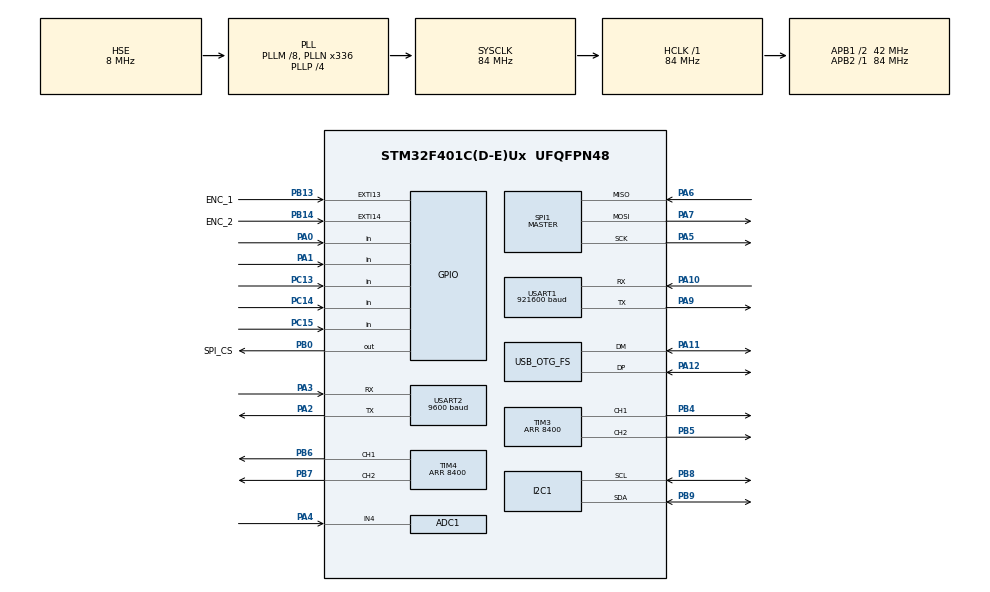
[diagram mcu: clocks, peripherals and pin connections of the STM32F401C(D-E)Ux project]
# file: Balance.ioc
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ADC1.Channel-0\#ChannelRegularConversion=ADC_CHANNEL_4
ADC1.ClockPrescaler=ADC_CLOCK_SYNC_PCLK_DIV4
ADC1.NbrOfConversionFlag=1
ADC1.Rank-0\#ChannelRegularConversion=1
ADC1.SamplingTime-0\#ChannelRegularConversion=ADC_SAMPLETIME_3CYCLES
ADC1.master=1
Dma.Request0=USART1_TX
Dma.Request1=USART1_RX
Dma.Request2=USART2_RX
Dma.Request3=USART2_TX
Dma.USART1_RX.1.Direction=DMA_PERIPH_TO_MEMORY
Dma.USART1_RX.1.FIFOMode=DMA_FIFOMODE_DISABLE
Dma.USART1_RX.1.Instance=DMA2_Stream2
Dma.USART1_RX.1.MemDataAlignment=DMA_MDATAALIGN_BYTE
Dma.USART1_RX.1.MemInc=DMA_MINC_ENABLE
Dma.USART1_RX.1.Mode=DMA_CIRCULAR
Dma.USART1_RX.1.PeriphDataAlignment=DMA_PDATAALIGN_BYTE
Dma.USART1_RX.1.PeriphInc=DMA_PINC_DISABLE
Dma.USART1_RX.1.Priority=DMA_PRIORITY_LOW
Dma.USART1_TX.0.Direction=DMA_MEMORY_TO_PERIPH
Dma.USART1_TX.0.FIFOMode=DMA_FIFOMODE_DISABLE
Dma.USART1_TX.0.Instance=DMA2_Stream7
Dma.USART1_TX.0.MemDataAlignment=DMA_MDATAALIGN_BYTE
Dma.USART1_TX.0.MemInc=DMA_MINC_ENABLE
Dma.USART1_TX.0.Mode=DMA_NORMAL
Dma.USART1_TX.0.PeriphDataAlignment=DMA_PDATAALIGN_BYTE
Dma.USART1_TX.0.PeriphInc=DMA_PINC_DISABLE
Dma.USART1_TX.0.Priority=DMA_PRIORITY_LOW
Dma.USART2_RX.2.Direction=DMA_PERIPH_TO_MEMORY
Dma.USART2_RX.2.FIFOMode=DMA_FIFOMODE_DISABLE
Dma.USART2_RX.2.Instance=DMA1_Stream5
Dma.USART2_RX.2.MemDataAlignment=DMA_MDATAALIGN_BYTE
Dma.USART2_RX.2.MemInc=DMA_MINC_ENABLE
Dma.USART2_RX.2.Mode=DMA_CIRCULAR
Dma.USART2_RX.2.PeriphDataAlignment=DMA_PDATAALIGN_BYTE
Dma.USART2_RX.2.PeriphInc=DMA_PINC_DISABLE
Dma.USART2_RX.2.Priority=DMA_PRIORITY_LOW
Dma.USART2_TX.3.Direction=DMA_MEMORY_TO_PERIPH
Dma.USART2_TX.3.FIFOMode=DMA_FIFOMODE_DISABLE
Dma.USART2_TX.3.Instance=DMA1_Stream6
Dma.USART2_TX.3.MemDataAlignment=DMA_MDATAALIGN_BYTE
Dma.USART2_TX.3.MemInc=DMA_MINC_ENABLE
Dma.USART2_TX.3.Mode=DMA_NORMAL
Dma.USART2_TX.3.PeriphDataAlignment=DMA_PDATAALIGN_BYTE
Dma.USART2_TX.3.PeriphInc=DMA_PINC_DISABLE
Dma.USART2_TX.3.Priority=DMA_PRIORITY_LOW
I2C1.I2C_Mode=I2C_Fast
Mcu.Family=STM32F4
Mcu.Name=STM32F401C(D-E)Ux
Mcu.Package=UFQFPN48
NVIC.DMA1_Stream5_IRQn=true\:3\:0\:true\:false\:true\:false\:true
NVIC.DMA1_Stream6_IRQn=true\:3\:0\:true\:false\:true\:false\:true
NVIC.DMA2_Stream2_IRQn=true\:3\:0\:true\:false\:true\:false\:true
NVIC.DMA2_Stream7_IRQn=true\:3\:0\:true\:false\:true\:false\:true
NVIC.EXTI15_10_IRQn=true\:2\:0\:true\:false\:true\:true\:true
NVIC.OTG_FS_IRQn=true\:2\:0\:true\:false\:true\:false\:true
NVIC.PriorityGroup=NVIC_PRIORITYGROUP_4
NVIC.TIM1_TRG_COM_TIM11_IRQn=true\:1\:0\:true\:false\:true\:true\:true
NVIC.TIM1_UP_TIM10_IRQn=true\:3\:0\:true\:false\:true\:false\:true
NVIC.TimeBase=TIM1_UP_TIM10_IRQn
NVIC.TimeBaseIP=TIM10
NVIC.USART1_IRQn=true\:3\:0\:true\:false\:true\:true\:true
NVIC.USART2_IRQn=true\:3\:0\:true\:false\:true\:true\:true
PA0-WKUP.Signal=GPIO_Input
PA1.Signal=GPIO_Input
PA10.Mode=Asynchronous
PA10.Signal=USART1_RX
PA11.Mode=Device_Only
PA11.Signal=USB_OTG_FS_DM
PA12.Mode=Device_Only
PA12.Signal=USB_OTG_FS_DP
PA13.Mode=Serial_Wire
PA13.Signal=SYS_JTMS-SWDIO
PA14.Mode=Serial_Wire
PA14.Signal=SYS_JTCK-SWCLK
PA2.Mode=Asynchronous
PA2.Signal=USART2_TX
PA3.Mode=Asynchronous
PA3.Signal=USART2_RX
PA4.Signal=ADCx_IN4
PA5.Mode=Full_Duplex_Master
PA5.Signal=SPI1_SCK
PA6.Mode=Full_Duplex_Master
PA6.Signal=SPI1_MISO
PA7.Mode=Full_Duplex_Master
PA7.Signal=SPI1_MOSI
PA9.Mode=Asynchronous
PA9.Signal=USART1_TX
PB0.GPIO_Label=SPI_CS
PB0.GPIO_PuPd=GPIO_PULLUP
PB0.GPIO_Speed=GPIO_SPEED_FREQ_HIGH
PB0.PinState=GPIO_PIN_SET
PB0.Signal=GPIO_Output
PB13.GPIO_Label=ENC_1
PB13.GPIO_ModeDefaultEXTI=GPIO_MODE_IT_RISING_FALLING
PB13.Signal=GPXTI13
PB14.GPIO_Label=ENC_2
PB14.GPIO_ModeDefaultEXTI=GPIO_MODE_IT_RISING_FALLING
PB14.Signal=GPXTI14
PB4.Signal=S_TIM3_CH1
PB5.Signal=S_TIM3_CH2
PB6.Signal=S_TIM4_CH1
PB7.Signal=S_TIM4_CH2
PB8.Mode=I2C
PB8.Signal=I2C1_SCL
PB9.Mode=I2C
PB9.Signal=I2C1_SDA
PC13-ANTI_TAMP.Signal=GPIO_Input
PC14-OSC32_IN.Signal=GPIO_Input
PC15-OSC32_OUT.Signal=GPIO_Input
PH0\ -\ OSC_IN.Mode=HSE-External-Oscillator
PH0\ -\ OSC_IN.Signal=RCC_OSC_IN
PH1\ -\ OSC_OUT.Mode=HSE-External-Oscillator
PH1\ -\ OSC_OUT.Signal=RCC_OSC_OUT
ProjectManager.HeapSize=0x100
ProjectManager.StackSize=0xA00
ProjectManager.TargetToolchain=MDK-ARM V5.27
RCC.48MHZClocksFreq_Value=48000000
RCC.AHBFreq_Value=84000000
RCC.APB1CLKDivider=RCC_HCLK_DIV2
RCC.APB1Freq_Value=42000000
RCC.APB1TimFreq_Value=84000000
RCC.APB2Freq_Value=84000000
RCC.APB2TimFreq_Value=84000000
RCC.CortexFreq_Value=84000000
RCC.HCLKFreq_Value=84000000
RCC.HSE_VALUE=8000000
RCC.HSI_VALUE=16000000
RCC.LSE_VALUE=32768
RCC.PLLM=8
RCC.PLLN=336
RCC.PLLP=RCC_PLLP_DIV4
RCC.PLLQ=7
RCC.SYSCLKFreq_VALUE=84000000
RCC.SYSCLKSource=RCC_SYSCLKSOURCE_PLLCLK
RCC.VCOOutputFreq_Value=336000000
SH.ADCx_IN4.0=ADC1_IN4,IN4
SH.S_TIM3_CH1.0=TIM3_CH1,PWM Generation1 CH1
SH.S_TIM3_CH2.0=TIM3_CH2,PWM Generation2 CH2
SH.S_TIM4_CH1.0=TIM4_CH1,PWM Generation1 CH1
SH.S_TIM4_CH2.0=TIM4_CH2,PWM Generation2 CH2
SPI1.Direction=SPI_DIRECTION_2LINES
SPI1.Mode=SPI_MODE_MASTER
SPI1.VirtualType=VM_MASTER
TIM11.AutoReloadPreload=TIM_AUTORELOAD_PRELOAD_ENABLE
TIM11.Period=1000/2-1
TIM11.Prescaler=84-1
TIM2.AutoReloadPreload=TIM_AUTORELOAD_PRELOAD_ENABLE
TIM2.Period=84000-1
TIM3.AutoReloadPreload=TIM_AUTORELOAD_PRELOAD_ENABLE
TIM3.Channel-PWM\ Generation1\ CH1=TIM_CHANNEL_1
TIM3.Channel-PWM\ Generation2\ CH2=TIM_CHANNEL_2
TIM3.OCMode_PWM-PWM\ Generation1\ CH1=TIM_OCMODE_PWM2
TIM3.OCMode_PWM-PWM\ Generation2\ CH2=TIM_OCMODE_PWM2
TIM3.Period=8400
TIM4.AutoReloadPreload=TIM_AUTORELOAD_PRELOAD_ENABLE
TIM4.Channel-PWM\ Generation1\ CH1=TIM_CHANNEL_1
TIM4.Channel-PWM\ Generation2\ CH2=TIM_CHANNEL_2
TIM4.OCMode_PWM-PWM\ Generation1\ CH1=TIM_OCMODE_PWM2
TIM4.OCMode_PWM-PWM\ Generation2\ CH2=TIM_OCMODE_PWM2
TIM4.Period=8400
USART1.BaudRate=921600
USART1.VirtualMode=VM_ASYNC
USART2.BaudRate=9600
USART2.VirtualMode=VM_ASYNC
USB_DEVICE.APP_RX_DATA_SIZE-CDC_FS=512
USB_DEVICE.APP_TX_DATA_SIZE-CDC_FS=512
USB_DEVICE.CLASS_NAME_FS=CDC
USB_DEVICE.VirtualMode-CDC_FS=Cdc
USB_DEVICE.VirtualModeFS=Cdc_FS
USB_OTG_FS.VirtualMode=Device_Only
VP_SYS_VS_tim10.Mode=TIM10
VP_TIM11_VS_ClockSourceINT.Mode=Enable_Timer
VP_TIM2_VS_ClockSourceINT.Mode=Internal
VP_TIM3_VS_ClockSourceINT.Mode=Internal
VP_TIM4_VS_ClockSourceINT.Mode=Internal
VP_USB_DEVICE_VS_USB_DEVICE_CDC_FS.Mode=CDC_FS
board=custom

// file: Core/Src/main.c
/* USER CODE BEGIN Header */
/**
  ******************************************************************************
  * @file           : main.c
  * @brief          : Main program body
  ******************************************************************************
  * @attention
  *
  * <h2><center>&copy; Copyright (c) 2021 STMicroelectronics.
  * All rights reserved.</center></h2>
  *
  * This software component is licensed by ST under BSD 3-Clause license,
  * the "License"; You may not use this file except in compliance with the
  * License. You may obtain a copy of the License at:
  *                        opensource.org/licenses/BSD-3-Clause
  *
  ******************************************************************************
  */
/* USER CODE END Header */
#include "main.h"
#include "adc.h"
#include "dma.h"
#include "i2c.h"
#include "spi.h"
#include "tim.h"
#include "usart.h"
#include "usb_device.h"
#include "gpio.h"

/* USER CODE BEGIN Includes */
extern void user_loop(void);
/* USER CODE END Includes */

void SystemClock_Config(void);

int main(void)
{

  /* MCU Configuration--------------------------------------------------------*/

  /* Reset of all peripherals, Initializes the Flash interface and the Systick. */
  HAL_Init();

  /* Configure the system clock */
  SystemClock_Config();

  /* Initialize all configured peripherals */
  MX_GPIO_Init();
  MX_DMA_Init();
  MX_ADC1_Init();
  MX_I2C1_Init();
  MX_SPI1_Init();
  MX_TIM3_Init();
  MX_TIM4_Init();
  MX_USART1_UART_Init();
  MX_USART2_UART_Init();
  MX_TIM11_Init();
  MX_TIM2_Init();
  MX_USB_DEVICE_Init();

  /* Infinite loop */
  /* USER CODE BEGIN WHILE */
  while (1)
  {
	  user_loop();
    /* USER CODE END WHILE */

  }
}

void SystemClock_Config(void)
{
  RCC_OscInitTypeDef RCC_OscInitStruct = {0};
  RCC_ClkInitTypeDef RCC_ClkInitStruct = {0};

  /** Configure the main internal regulator output voltage
  */
  __HAL_RCC_PWR_CLK_ENABLE();
  __HAL_PWR_VOLTAGESCALING_CONFIG(PWR_REGULATOR_VOLTAGE_SCALE2);
  /** Initializes the RCC Oscillators according to the specified parameters
  * in the RCC_OscInitTypeDef structure.
  */
  RCC_OscInitStruct.OscillatorType = RCC_OSCILLATORTYPE_HSE;
  RCC_OscInitStruct.HSEState = RCC_HSE_ON;
  RCC_OscInitStruct.PLL.PLLState = RCC_PLL_ON;
  RCC_OscInitStruct.PLL.PLLSource = RCC_PLLSOURCE_HSE;
  RCC_OscInitStruct.PLL.PLLM = 8;
  RCC_OscInitStruct.PLL.PLLN = 336;
  RCC_OscInitStruct.PLL.PLLP = RCC_PLLP_DIV4;
  RCC_OscInitStruct.PLL.PLLQ = 7;
  if (HAL_RCC_OscConfig(&RCC_OscInitStruct) != HAL_OK)
  {
    Error_Handler();
  }
  /** Initializes the CPU, AHB and APB buses clocks
  */
  RCC_ClkInitStruct.ClockType = RCC_CLOCKTYPE_HCLK|RCC_CLOCKTYPE_SYSCLK
                              |RCC_CLOCKTYPE_PCLK1|RCC_CLOCKTYPE_PCLK2;
  RCC_ClkInitStruct.SYSCLKSource = RCC_SYSCLKSOURCE_PLLCLK;
  RCC_ClkInitStruct.AHBCLKDivider = RCC_SYSCLK_DIV1;
  RCC_ClkInitStruct.APB1CLKDivider = RCC_HCLK_DIV2;
  RCC_ClkInitStruct.APB2CLKDivider = RCC_HCLK_DIV1;

  if (HAL_RCC_ClockConfig(&RCC_ClkInitStruct, FLASH_LATENCY_2) != HAL_OK)
  {
    Error_Handler();
  }
}

 /**
  * @brief  Period elapsed callback in non blocking mode
  * @note   This function is called  when TIM10 interrupt took place, inside
  * HAL_TIM_IRQHandler(). It makes a direct call to HAL_IncTick() to increment
  * a global variable "uwTick" used as application time base.
  * @param  htim : TIM handle
  * @retval None
  */
__weak void HAL_TIM_PeriodElapsedCallback(TIM_HandleTypeDef *htim)
{
  if (htim->Instance == TIM10) {
    HAL_IncTick();
  }
}

void Error_Handler(void)
{
  __disable_irq();
  while (1)
  {
  }
}

/************************ (C) COPYRIGHT STMicroelectronics *****END OF FILE****/
